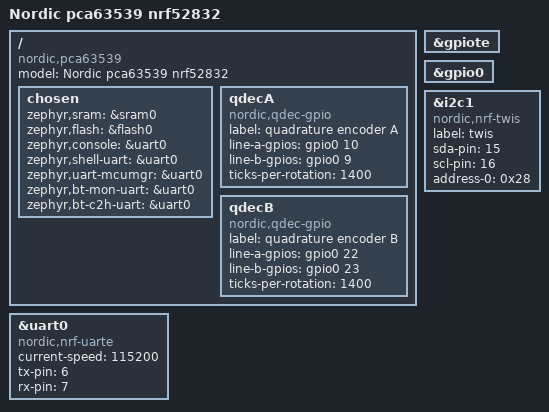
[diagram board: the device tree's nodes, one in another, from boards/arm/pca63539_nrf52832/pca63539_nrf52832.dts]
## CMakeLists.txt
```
cmake_minimum_required(VERSION 3.16.0)

if (NOT CMAKE_BUILD_TYPE)
  set(CMAKE_BUILD_TYPE ZDebug)
endif()

list(APPEND BOARD_ROOT ${CMAKE_CURRENT_SOURCE_DIR})

set(CMAKE_EXPORT_COMPILE_COMMANDS ON)

find_package(Zephyr REQUIRED HINTS $ENV{ZEPHYR_BASE})
project("Balancing-robot-shield-firmware")

target_sources(
app PRIVATE src/main.c
)

target_include_directories(app PRIVATE src)

add_subdirectory(drivers)
```

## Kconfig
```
menu "Balancing robot shield"
rsource "drivers/Kconfig"
endmenu

menu "Zephyr Kernel"
source "Kconfig.zephyr"
endmenu

module = APPLICATION_MODULE
module-str = application
source "subsys/logging/Kconfig.template.log_config"
```

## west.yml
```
manifest:
  version: "0.10"

  defaults:
    revision: main

  remotes:
    - name: nrfconnect
      url-base: https://github.com/nrfconnect/

  projects:
    - name: sdk-nrf
      remote: nrfconnect
      path: nrf
      revision: v1.8.0 
      import: true
      
  self:
    path: balancing-robot-shield-firmware
```

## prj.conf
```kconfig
CONFIG_ASSERT=y

CONFIG_HEAP_MEM_POOL_SIZE=16384
CONFIG_MAIN_STACK_SIZE=4096

CONFIG_DEBUG=y

CONFIG_CONSOLE=y
CONFIG_UART_CONSOLE=n
CONFIG_RTT_CONSOLE=y
CONFIG_USE_SEGGER_RTT=y

# Logger configuration
CONFIG_LOG=y
CONFIG_LOG_DEFAULT_LEVEL=4
CONFIG_LOG_STRDUP_BUF_COUNT=20
CONFIG_LOG_STRDUP_MAX_STRING=128

CONFIG_APPLICATION_MODULE_LOG_LEVEL_DBG=y
```

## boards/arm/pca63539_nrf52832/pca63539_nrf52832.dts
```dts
/dts-v1/;

#include <nordic/nrf52832_qfaa.dtsi>

/ {
	model = "Nordic pca63539 nrf52832";
	compatible = "nordic,pca63539";

	chosen {
		zephyr,sram = &sram0;
		zephyr,flash = &flash0;
		zephyr,console = &uart0;
		zephyr,shell-uart = &uart0;
		zephyr,uart-mcumgr = &uart0;
		zephyr,bt-mon-uart = &uart0;
		zephyr,bt-c2h-uart = &uart0;
	};

	qdecA: qdecA {
		    compatible = "nordic,qdec-gpio";
		    status = "okay";
		    label = "quadrature encoder A";
		    line-a-gpios = <&gpio0 10 0>;
		    line-b-gpios = <&gpio0 9 0>;
		    ticks-per-rotation = <1400>;
	};

	qdecB: qdecB {
		compatible = "nordic,qdec-gpio";
		status = "okay";
		label = "quadrature encoder B";
		line-a-gpios = <&gpio0 22 0>;
		line-b-gpios = <&gpio0 23 0>;
		ticks-per-rotation = <1400>;
	};
};

&gpiote {
	status = "okay";
};

&gpio0 {
	status = "okay";
};

&uart0 {
	status = "okay";
	compatible = "nordic,nrf-uarte";
	current-speed = <115200>;
	tx-pin = <6>;
	rx-pin = <7>;
};


&i2c1 {
	status = "okay";
	compatible = "nordic,nrf-twis";
	label="twis";
	sda-pin = <15>;
	scl-pin = <16>;
	address-0 = <0x28>;
};
```

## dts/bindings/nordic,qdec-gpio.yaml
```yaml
description: |
  GPIO based quadrature decoder.
compatible: "nordic,qdec-gpio"

include:  "base.yaml"

properties:
  label:
    type: string
    description: |
      Human readable name for the device.

  line-a-gpios:
    required: true
    type: phandle-array
    description: |
      Encoder line A

  line-b-gpios:
    required: true
    type: phandle-array
    description: |
      Encoder line B

  ticks-per-rotation:
    required: true
    type: int
    description: |
      Number of ticks per rotation
```

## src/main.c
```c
#define MODULE main

#include <zephyr.h>
#include <device.h>
#include <drivers/sensor.h>

#include <drivers/gpio.h>
#include <drivers/uart.h>
#include <nrfx_twis.h>

#include <logging/log.h>
LOG_MODULE_REGISTER(application, CONFIG_LOG_DEFAULT_LEVEL);

static struct device *qdeca_dev;
static struct device *qdecb_dev;


static struct shield_tx_data
{
    struct sensor_value motor_a_pos;
    struct sensor_value motor_b_pos;
} twis_tx_buf;

#define TWI_BUF_SIZE 512

static unsigned char twis_rx_buf[TWI_BUF_SIZE];
const nrfx_twis_t twis_inst = NRFX_TWIS_INSTANCE(1);

static void twis_write_done_handler(void* buffer, uint32_t size){
    LOG_DBG("Data recieved from controller");
}

static void twis_event_handler(nrfx_twis_evt_t const *const p_event)
{
    LOG_DBG("NRFX TWIS event");
    switch(p_event->type){
        case NRFX_TWIS_EVT_READ_REQ: {
            LOG_DBG("NRFX_TWIS_EVT_READ_REQ");
            if (p_event->data.buf_req){
                sensor_sample_fetch(qdeca_dev);
                sensor_channel_get(qdeca_dev, SENSOR_CHAN_ROTATION, &twis_tx_buf.motor_a_pos);

                sensor_sample_fetch(qdecb_dev);
                sensor_channel_get(qdecb_dev, SENSOR_CHAN_ROTATION, &twis_tx_buf.motor_b_pos);
                LOG_DBG("Sending motor A position: %d.%d  motor B position: %d.%d", twis_tx_buf.motor_a_pos.val1, twis_tx_buf.motor_a_pos.val2, twis_tx_buf.motor_b_pos.val1,twis_tx_buf.motor_b_pos.val2);
                nrfx_twis_tx_prepare(&twis_inst, (void*) &twis_tx_buf, sizeof(twis_tx_buf));
            }

            break;
        }
        case NRFX_TWIS_EVT_READ_DONE: {
            LOG_DBG("NRFX_TWIS_EVT_READ_DONE");
            break;
        }
        case NRFX_TWIS_EVT_WRITE_REQ: {
            LOG_DBG("NRFX_TWIS_EVT_WRITE_REQ");
            if (p_event->data.buf_req){
                nrfx_twis_tx_prepare(&twis_inst, (void*) twis_rx_buf, sizeof(twis_rx_buf));
            }
            break;
        }
        case NRFX_TWIS_EVT_WRITE_DONE: {
            LOG_DBG("NRFX_TWIS_EVT_WRITE_DONE");
            twis_write_done_handler(twis_rx_buf, p_event->data.rx_amount);
            break;
        }
        case NRFX_TWIS_EVT_READ_ERROR:
        case NRFX_TWIS_EVT_WRITE_ERROR:
        case NRFX_TWIS_EVT_GENERAL_ERROR: {
            LOG_ERR("TWIS error: %d", p_event->type);
            break;
        }
    }
}

static int twis_init()
{
    nrfx_twis_config_t config;

#define TWIS_NODE DT_NODELABEL(i2c1)
    config.sda = DT_PROP(TWIS_NODE, sda_pin);
    config.sda_pull = NRF_GPIO_PIN_PULLUP;
    config.scl = DT_PROP(TWIS_NODE, scl_pin);
    config.scl_pull = NRF_GPIO_PIN_PULLUP;
    config.addr[0] = DT_PROP(TWIS_NODE, address_0);
    // address-1 field is optional. Default to 0 to disable.
#if (DT_NODE_HAS_PROP(TWIS_NODE, address_1))
    config.addr[1] = DT_PROP(TWIS_NODE, address_1);
#else
    config.addr[1] = 0;
#endif
    config.interrupt_priority = DT_IRQ(DT_NODELABEL(i2c1), priority);

    IRQ_CONNECT(DT_IRQN(DT_NODELABEL(i2c1)), DT_IRQ(DT_NODELABEL(i2c1), priority), nrfx_isr, nrfx_twis_1_irq_handler, 0);
    if (nrfx_twis_init(&twis_inst, &config, twis_event_handler) != NRFX_SUCCESS)
    {
        LOG_ERR("TWIS init failed");
        return -1;
    }
    nrfx_twis_enable(&twis_inst);
    return 0;
}

void main()
{
    LOG_DBG("Starting shield firmware");
    qdeca_dev = device_get_binding(DT_LABEL(DT_NODELABEL(qdeca)));
    qdecb_dev = device_get_binding(DT_LABEL(DT_NODELABEL(qdecb)));
    if (qdeca_dev == NULL || qdecb_dev == NULL)
    {
        LOG_ERR("Failed to get bindings for qdec devices");
        return;
    }
    twis_init();
}
```
